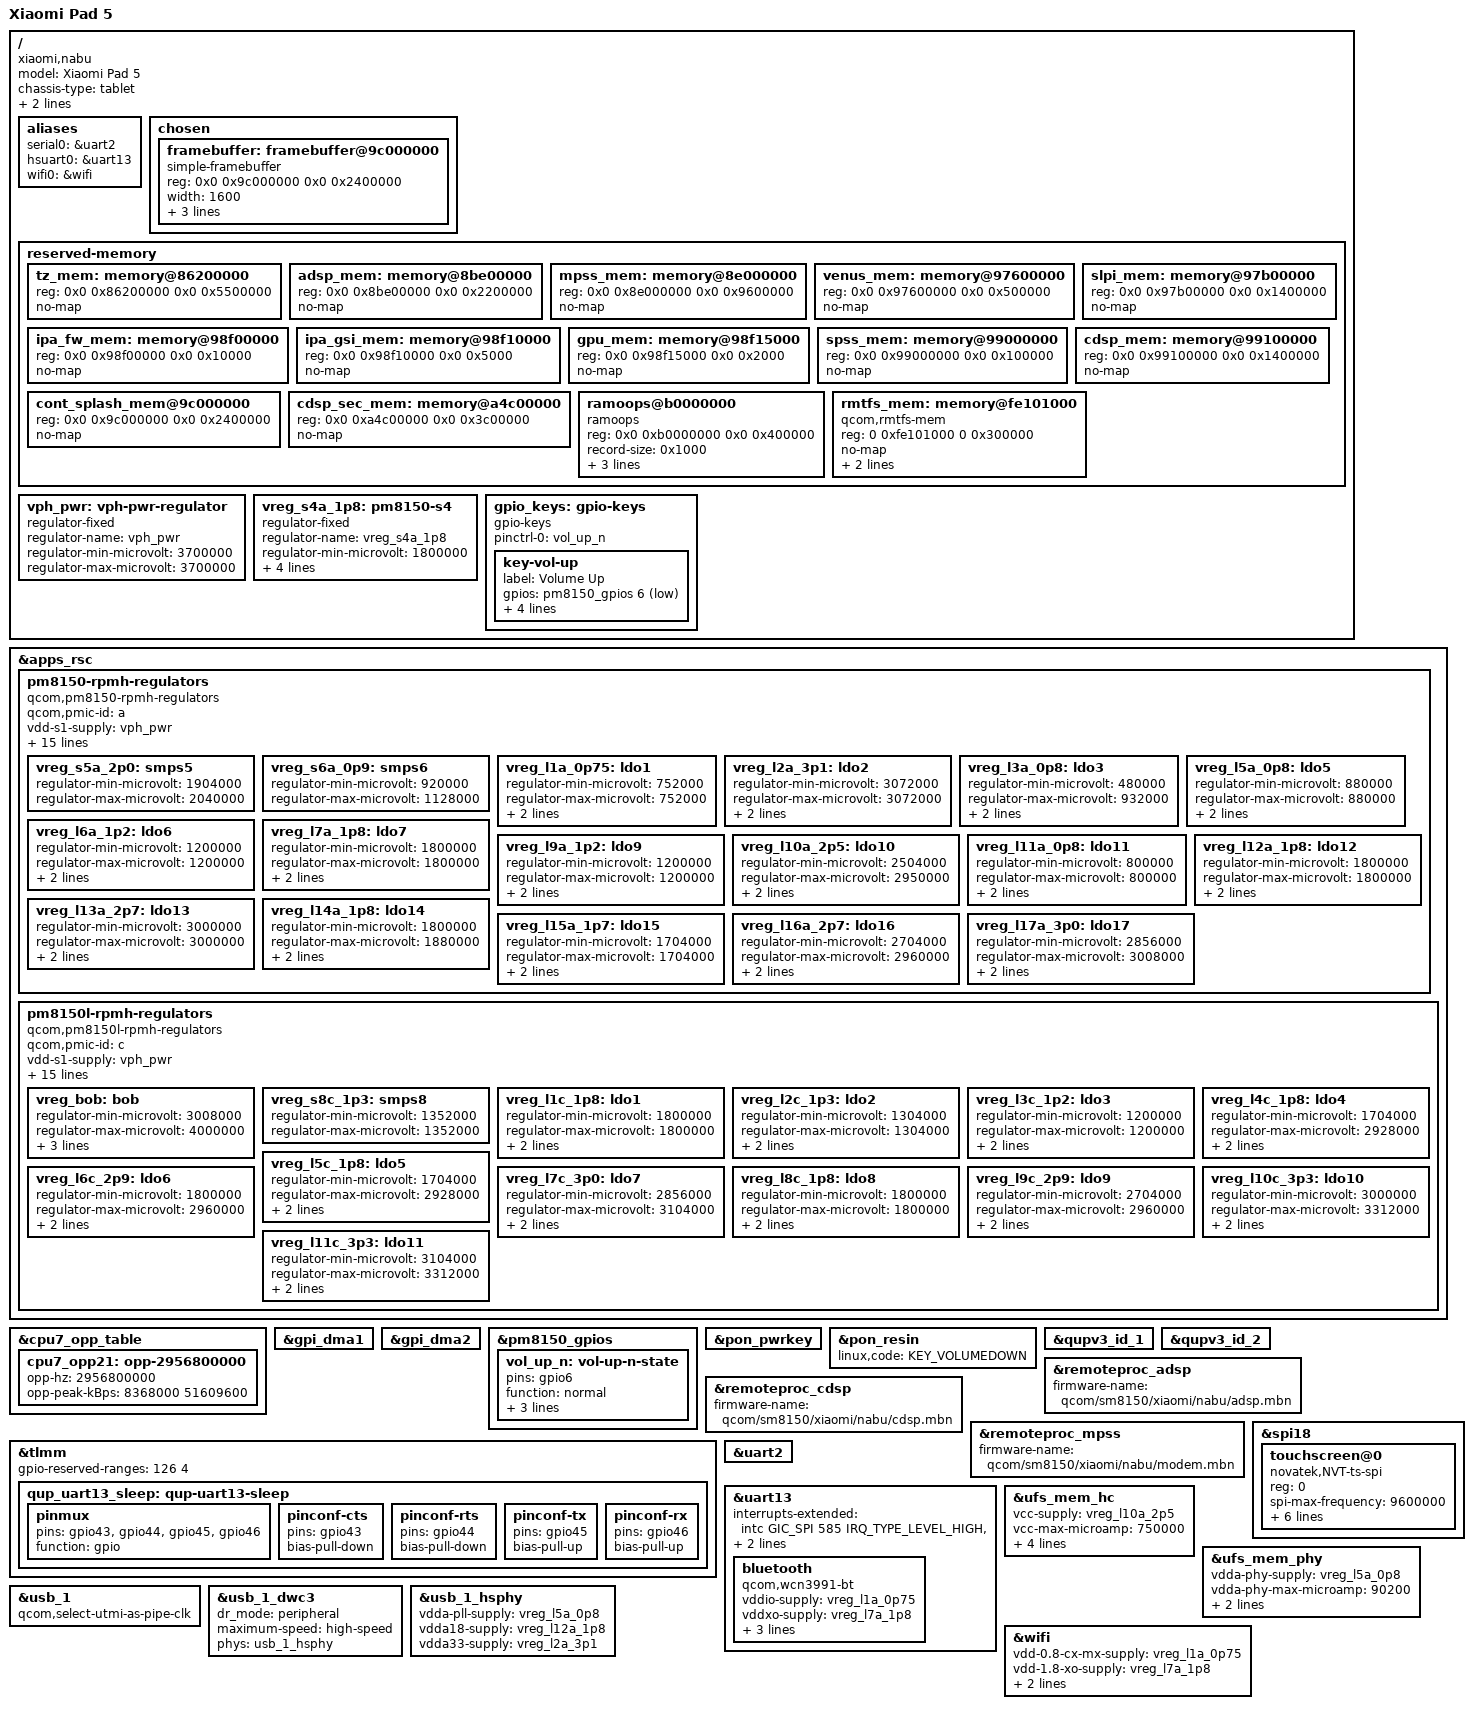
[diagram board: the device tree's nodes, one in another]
// SPDX-License-Identifier: BSD-3-Clause
/*
 * Copyright (c) 2023, map220v <map220v300@gmail.com>
 */

/dts-v1/;

#include <dt-bindings/arm/qcom,ids.h>
#include <dt-bindings/gpio/gpio.h>
#include <dt-bindings/regulator/qcom,rpmh-regulator.h>
#include "sm8150.dtsi"
#include "pm8150.dtsi"
#include "pm8150b.dtsi"
#include "pm8150l.dtsi"

/delete-node/ &tz_mem;
/delete-node/ &rmtfs_mem;
/delete-node/ &adsp_mem;
/delete-node/ &mpss_mem;
/delete-node/ &venus_mem;
/delete-node/ &slpi_mem;
/delete-node/ &ipa_fw_mem;
/delete-node/ &ipa_gsi_mem;
/delete-node/ &gpu_mem;
/delete-node/ &spss_mem;
/delete-node/ &cdsp_mem;

/ {
	model = "Xiaomi Pad 5";
	compatible = "xiaomi,nabu", "qcom,sm8150";
	chassis-type = "tablet";
	qcom,msm-id = <QCOM_ID_SM8150 0x20002>; /* SM8150 v2.2 */
	qcom,board-id = <48 0>;

	aliases {
		serial0 = &uart2;
		hsuart0 = &uart13;
		wifi0 = &wifi;
	};

	chosen {
		#address-cells = <2>;
		#size-cells = <2>;
		ranges;

		framebuffer: framebuffer@9c000000 {
			compatible = "simple-framebuffer";
			reg = <0x0 0x9c000000 0x0 0x2400000>;
			width = <1600>;
			height = <2560>;
			stride = <(1600 * 4)>;
			format = "a8r8g8b8";
		};
	};

	reserved-memory {
		#address-cells = <2>;
		#size-cells = <2>;
		ranges;

		tz_mem: memory@86200000 {
			reg = <0x0 0x86200000 0x0 0x5500000>;
			no-map;
		};

		adsp_mem: memory@8be00000 {
			reg = <0x0 0x8be00000 0x0 0x2200000>;
			no-map;
		};

		mpss_mem: memory@8e000000 {
			reg = <0x0 0x8e000000 0x0 0x9600000>;
			no-map;
		};

		venus_mem: memory@97600000 {
			reg = <0x0 0x97600000 0x0 0x500000>;
			no-map;
		};

		slpi_mem: memory@97b00000 {
			reg = <0x0 0x97b00000 0x0 0x1400000>;
			no-map;
		};

		ipa_fw_mem: memory@98f00000 {
			reg = <0x0 0x98f00000 0x0 0x10000>;
			no-map;
		};

		ipa_gsi_mem: memory@98f10000 {
			reg = <0x0 0x98f10000 0x0 0x5000>;
			no-map;
		};

		gpu_mem: memory@98f15000 {
			reg = <0x0 0x98f15000 0x0 0x2000>;
			no-map;
		};

		spss_mem: memory@99000000 {
			reg = <0x0 0x99000000 0x0 0x100000>;
			no-map;
		};

		cdsp_mem: memory@99100000 {
			reg = <0x0 0x99100000 0x0 0x1400000>;
			no-map;
		};

		cont_splash_mem@9c000000 {
			reg = <0x0 0x9c000000 0x0 0x2400000>;
			no-map;
		};

		cdsp_sec_mem: memory@a4c00000 {
			reg = <0x0 0xa4c00000 0x0 0x3c00000>;
			no-map;
		};

		ramoops@b0000000 {
			compatible = "ramoops";
			reg = <0x0 0xb0000000 0x0 0x400000>;
			record-size = <0x1000>;
			console-size = <0x200000>;
			ecc-size = <16>;
			no-map;
		};

		rmtfs_mem: memory@fe101000 {
			compatible = "qcom,rmtfs-mem";
			reg = <0 0xfe101000 0 0x300000>;
			no-map;

			qcom,client-id = <1>;
			qcom,vmid = <15>;
		};
	};

	vph_pwr: vph-pwr-regulator {
		compatible = "regulator-fixed";
		regulator-name = "vph_pwr";
		regulator-min-microvolt = <3700000>;
		regulator-max-microvolt = <3700000>;
	};

	/*
	 * Apparently RPMh does not provide support for PM8150 S4 because it
	 * is always-on; model it as a fixed regulator.
	 */
	vreg_s4a_1p8: pm8150-s4 {
		compatible = "regulator-fixed";
		regulator-name = "vreg_s4a_1p8";

		regulator-min-microvolt = <1800000>;
		regulator-max-microvolt = <1800000>;

		regulator-always-on;
		regulator-boot-on;

		vin-supply = <&vph_pwr>;
	};

	gpio_keys: gpio-keys {
		compatible = "gpio-keys";

		pinctrl-names = "default";
		pinctrl-0 = <&vol_up_n>;

		key-vol-up {
			label = "Volume Up";
			gpios = <&pm8150_gpios 6 GPIO_ACTIVE_LOW>;
			linux,code = <KEY_VOLUMEUP>;
			debounce-interval = <15>;
			linux,can-disable;
			wakeup-source;
		};
	};
};

&apps_rsc {
	pm8150-rpmh-regulators {
		compatible = "qcom,pm8150-rpmh-regulators";
		qcom,pmic-id = "a";

		vdd-s1-supply = <&vph_pwr>;
		vdd-s2-supply = <&vph_pwr>;
		vdd-s3-supply = <&vph_pwr>;
		vdd-s4-supply = <&vph_pwr>;
		vdd-s5-supply = <&vph_pwr>;
		vdd-s6-supply = <&vph_pwr>;
		vdd-s7-supply = <&vph_pwr>;
		vdd-s8-supply = <&vph_pwr>;
		vdd-s9-supply = <&vph_pwr>;
		vdd-s10-supply = <&vph_pwr>;

		vdd-l1-l8-l11-supply = <&vreg_s6a_0p9>;
		vdd-l2-l10-supply = <&vreg_bob>;
		vdd-l3-l4-l5-l18-supply = <&vreg_s6a_0p9>;
		vdd-l6-l9-supply = <&vreg_s8c_1p3>;
		vdd-l7-l12-l14-l15-supply = <&vreg_s5a_2p0>;
		vdd-l13-l16-l17-supply = <&vreg_bob>;

		vreg_s5a_2p0: smps5 {
			regulator-min-microvolt = <1904000>;
			regulator-max-microvolt = <2040000>;
		};

		vreg_s6a_0p9: smps6 {
			regulator-min-microvolt = <920000>;
			regulator-max-microvolt = <1128000>;
		};

		vreg_l1a_0p75: ldo1 {
			regulator-min-microvolt = <752000>;
			regulator-max-microvolt = <752000>;
			regulator-initial-mode = <RPMH_REGULATOR_MODE_HPM>;
		};

		vreg_l2a_3p1: ldo2 {
			regulator-min-microvolt = <3072000>;
			regulator-max-microvolt = <3072000>;
			regulator-initial-mode = <RPMH_REGULATOR_MODE_HPM>;
		};

		vreg_l3a_0p8: ldo3 {
			regulator-min-microvolt = <480000>;
			regulator-max-microvolt = <932000>;
			regulator-initial-mode = <RPMH_REGULATOR_MODE_HPM>;
		};

		vreg_l5a_0p8: ldo5 {
			regulator-min-microvolt = <880000>;
			regulator-max-microvolt = <880000>;
			regulator-initial-mode = <RPMH_REGULATOR_MODE_HPM>;
		};

		vreg_l6a_1p2: ldo6 {
			regulator-min-microvolt = <1200000>;
			regulator-max-microvolt = <1200000>;
			regulator-initial-mode = <RPMH_REGULATOR_MODE_HPM>;
		};

		vreg_l7a_1p8: ldo7 {
			regulator-min-microvolt = <1800000>;
			regulator-max-microvolt = <1800000>;
			regulator-initial-mode = <RPMH_REGULATOR_MODE_HPM>;
		};

		vreg_l9a_1p2: ldo9 {
			regulator-min-microvolt = <1200000>;
			regulator-max-microvolt = <1200000>;
			regulator-initial-mode = <RPMH_REGULATOR_MODE_HPM>;
		};

		vreg_l10a_2p5: ldo10 {
			regulator-min-microvolt = <2504000>;
			regulator-max-microvolt = <2950000>;
			regulator-initial-mode = <RPMH_REGULATOR_MODE_HPM>;
		};

		vreg_l11a_0p8: ldo11 {
			regulator-min-microvolt = <800000>;
			regulator-max-microvolt = <800000>;
			regulator-initial-mode = <RPMH_REGULATOR_MODE_HPM>;
		};

		vreg_l12a_1p8: ldo12 {
			regulator-min-microvolt = <1800000>;
			regulator-max-microvolt = <1800000>;
			regulator-initial-mode = <RPMH_REGULATOR_MODE_HPM>;
		};

		vreg_l13a_2p7: ldo13 {
			regulator-min-microvolt = <3000000>;
			regulator-max-microvolt = <3000000>;
			regulator-initial-mode = <RPMH_REGULATOR_MODE_HPM>;
		};

		vreg_l14a_1p8: ldo14 {
			regulator-min-microvolt = <1800000>;
			regulator-max-microvolt = <1880000>;
			regulator-initial-mode = <RPMH_REGULATOR_MODE_HPM>;
		};

		vreg_l15a_1p7: ldo15 {
			regulator-min-microvolt = <1704000>;
			regulator-max-microvolt = <1704000>;
			regulator-initial-mode = <RPMH_REGULATOR_MODE_HPM>;
		};

		vreg_l16a_2p7: ldo16 {
			regulator-min-microvolt = <2704000>;
			regulator-max-microvolt = <2960000>;
			regulator-initial-mode = <RPMH_REGULATOR_MODE_HPM>;
		};

		vreg_l17a_3p0: ldo17 {
			regulator-min-microvolt = <2856000>;
			regulator-max-microvolt = <3008000>;
			regulator-initial-mode = <RPMH_REGULATOR_MODE_HPM>;
		};
	};

	pm8150l-rpmh-regulators {
		compatible = "qcom,pm8150l-rpmh-regulators";
		qcom,pmic-id = "c";

		vdd-s1-supply = <&vph_pwr>;
		vdd-s2-supply = <&vph_pwr>;
		vdd-s3-supply = <&vph_pwr>;
		vdd-s4-supply = <&vph_pwr>;
		vdd-s5-supply = <&vph_pwr>;
		vdd-s6-supply = <&vph_pwr>;
		vdd-s7-supply = <&vph_pwr>;
		vdd-s8-supply = <&vph_pwr>;

		vdd-l1-l8-supply = <&vreg_s4a_1p8>;
		vdd-l2-l3-supply = <&vreg_s8c_1p3>;
		vdd-l4-l5-l6-supply = <&vreg_bob>;
		vdd-l7-l11-supply = <&vreg_bob>;
		vdd-l9-l10-supply = <&vreg_bob>;

		vdd-bob-supply = <&vph_pwr>;
		vdd-flash-supply = <&vreg_bob>;
		vdd-rgb-supply = <&vreg_bob>;

		vreg_bob: bob {
			regulator-min-microvolt = <3008000>;
			regulator-max-microvolt = <4000000>;
			regulator-initial-mode = <RPMH_REGULATOR_MODE_AUTO>;
			regulator-allow-bypass;
		};

		vreg_s8c_1p3: smps8 {
			regulator-min-microvolt = <1352000>;
			regulator-max-microvolt = <1352000>;
		};

		vreg_l1c_1p8: ldo1 {
			regulator-min-microvolt = <1800000>;
			regulator-max-microvolt = <1800000>;
			regulator-initial-mode = <RPMH_REGULATOR_MODE_HPM>;
		};

		vreg_l2c_1p3: ldo2 {
			regulator-min-microvolt = <1304000>;
			regulator-max-microvolt = <1304000>;
			regulator-initial-mode = <RPMH_REGULATOR_MODE_HPM>;
		};

		vreg_l3c_1p2: ldo3 {
			regulator-min-microvolt = <1200000>;
			regulator-max-microvolt = <1200000>;
			regulator-initial-mode = <RPMH_REGULATOR_MODE_HPM>;
		};

		vreg_l4c_1p8: ldo4 {
			regulator-min-microvolt = <1704000>;
			regulator-max-microvolt = <2928000>;
			regulator-initial-mode = <RPMH_REGULATOR_MODE_HPM>;
		};

		vreg_l5c_1p8: ldo5 {
			regulator-min-microvolt = <1704000>;
			regulator-max-microvolt = <2928000>;
			regulator-initial-mode = <RPMH_REGULATOR_MODE_HPM>;
		};

		vreg_l6c_2p9: ldo6 {
			regulator-min-microvolt = <1800000>;
			regulator-max-microvolt = <2960000>;
			regulator-initial-mode = <RPMH_REGULATOR_MODE_HPM>;
		};

		vreg_l7c_3p0: ldo7 {
			regulator-min-microvolt = <2856000>;
			regulator-max-microvolt = <3104000>;
			regulator-initial-mode = <RPMH_REGULATOR_MODE_HPM>;
		};

		vreg_l8c_1p8: ldo8 {
			regulator-min-microvolt = <1800000>;
			regulator-max-microvolt = <1800000>;
			regulator-initial-mode = <RPMH_REGULATOR_MODE_HPM>;
		};

		vreg_l9c_2p9: ldo9 {
			regulator-min-microvolt = <2704000>;
			regulator-max-microvolt = <2960000>;
			regulator-initial-mode = <RPMH_REGULATOR_MODE_HPM>;
		};

		vreg_l10c_3p3: ldo10 {
			regulator-min-microvolt = <3000000>;
			regulator-max-microvolt = <3312000>;
			regulator-initial-mode = <RPMH_REGULATOR_MODE_HPM>;
		};

		vreg_l11c_3p3: ldo11 {
			regulator-min-microvolt = <3104000>;
			regulator-max-microvolt = <3312000>;
			regulator-initial-mode = <RPMH_REGULATOR_MODE_HPM>;
		};
	};

	/* PM8009 is not present on these boards, even if downstream sources suggest so. */
};

//SD860 additional cpu frequency
&cpu7_opp_table {
	cpu7_opp21: opp-2956800000 {
		opp-hz = /bits/ 64 <2956800000>;
		opp-peak-kBps = <8368000 51609600>;
	};
};

&gpi_dma1 {
	status = "okay";
};

&gpi_dma2 {
	status = "okay";
};

&pm8150_gpios {
	vol_up_n: vol-up-n-state {
		pins = "gpio6";
		function = "normal";
		power-source = <1>;
		input-enable;
		bias-pull-up;
	};
};

&pon_pwrkey {
	status = "okay";
};

&pon_resin {
	linux,code = <KEY_VOLUMEDOWN>;
	status = "okay";
};

&qupv3_id_1 {
	status = "okay";
};

&qupv3_id_2 {
	status = "okay";
};

&remoteproc_adsp {
	status = "okay";
	firmware-name = "qcom/sm8150/xiaomi/nabu/adsp.mbn";
};

&remoteproc_cdsp {
	status = "okay";
	firmware-name = "qcom/sm8150/xiaomi/nabu/cdsp.mbn";
};

&remoteproc_mpss {
	status = "okay";
	firmware-name = "qcom/sm8150/xiaomi/nabu/modem.mbn";
};

&spi18 {
	status = "okay";

	touchscreen@0 {
		compatible = "novatek,NVT-ts-spi";
		reg = <0>;

		spi-max-frequency = <9600000>;
		novatek,irq-gpio = <&tlmm 39 0x2001>;

		novatek,pen-support;
		novatek,wgp-stylus;

		/* 523 */
		novatek,swrst-n8-addr = <0x03F0FE>;
		novatek,spi-rd-fast-addr = <0x03F310>;

		firmware-name = "novatek/novatek_nt36523_fw.bin";
	};
};

&tlmm {
	gpio-reserved-ranges = <126 4>;

	qup_uart13_sleep: qup-uart13-sleep {
		pinmux {
			pins = "gpio43", "gpio44",
			       "gpio45", "gpio46";
			function = "gpio";
		};

		pinconf-cts {
			/*
			 * Configure a pull-down on CTS to match the pull of
			 * the Bluetooth module.
			 */
			pins = "gpio43";
			bias-pull-down;
		};

		pinconf-rts {
			/*
			 * Configure pull-down on RTS. As RTS is active low
			 * signal, pull it low to indicate the BT SoC that it
			 * can wakeup the system anytime from suspend state by
			 * pulling RX low (by sending wakeup bytes).
			 */
			 pins = "gpio44";
			 bias-pull-down;
		};

		pinconf-tx {
			/*
			 * Configure pull-up on TX when it isn't actively driven
			 * to prevent BT SoC from receiving garbage during sleep.
			 */
			pins = "gpio45";
			bias-pull-up;
		};

		pinconf-rx {
			/*
			 * Configure a pull-up on RX. This is needed to avoid
			 * garbage data when the TX pin of the Bluetooth module
			 * is floating which may cause spurious wakeups.
			 */
			pins = "gpio46";
			bias-pull-up;
		};
	};
};

&uart2 {
	status = "okay";
};

&uart13 {
	status = "okay";

	/delete-property/interrupts;
	interrupts-extended = <&intc GIC_SPI 585 IRQ_TYPE_LEVEL_HIGH>,
				<&tlmm 46 IRQ_TYPE_EDGE_FALLING>;

	pinctrl-names = "default", "sleep";
	pinctrl-1 = <&qup_uart13_sleep>;

	bluetooth: bluetooth {
		compatible = "qcom,wcn3991-bt";
		vddio-supply = <&vreg_l1a_0p75>;
		vddxo-supply = <&vreg_l7a_1p8>;
		vddrf-supply = <&vreg_l2c_1p3>;
		vddch0-supply = <&vreg_l11c_3p3>;
		max-speed = <3200000>;
	};
};

&ufs_mem_hc {
	status = "okay";

	vcc-supply = <&vreg_l10a_2p5>;
	vcc-max-microamp = <750000>;
	vccq-supply = <&vreg_l9a_1p2>;
	vccq-max-microamp = <700000>;
	vccq2-supply = <&vreg_s4a_1p8>;
	vccq2-max-microamp = <750000>;
};

&ufs_mem_phy {
	status = "okay";

	vdda-phy-supply = <&vreg_l5a_0p8>;
	vdda-phy-max-microamp = <90200>;
	vdda-pll-supply = <&vreg_l3c_1p2>;
	vdda-pll-max-microamp = <19000>;
};

&usb_1 {
	/* USB 2.0 only */
	qcom,select-utmi-as-pipe-clk;
	status = "okay";
};

&usb_1_dwc3 {
	dr_mode = "peripheral";
	maximum-speed = "high-speed";
	/* Remove USB3 phy */
	phys = <&usb_1_hsphy>;
	phy-names = "usb2-phy";
};

&usb_1_hsphy {
	vdda-pll-supply = <&vreg_l5a_0p8>;
	vdda18-supply = <&vreg_l12a_1p8>;
	vdda33-supply = <&vreg_l2a_3p1>;
	status = "okay";
};

&wifi {
	status = "okay";

	vdd-0.8-cx-mx-supply = <&vreg_l1a_0p75>;
	vdd-1.8-xo-supply = <&vreg_l7a_1p8>;
	vdd-1.3-rfa-supply = <&vreg_l2c_1p3>;
	vdd-3.3-ch0-supply = <&vreg_l11c_3p3>;
};
